# iostr911f register map
Registers are 16-bit, access not given, no defined reset value unless marked. A register's access mark holds for its fields unless they carry their own. Addresses are absolute; registers are grouped by the start of their names; [hi:lo] are bit positions; {n}, {i} and the like mark numbered series; 'fields as' and 'values as' point back to an identical list.

## SCU
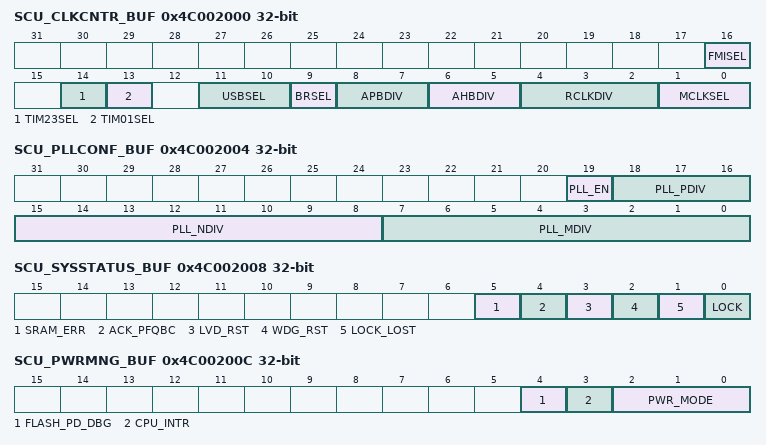
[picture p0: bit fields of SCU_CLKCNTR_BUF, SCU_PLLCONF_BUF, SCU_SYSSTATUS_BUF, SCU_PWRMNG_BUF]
0x4C002000 SCU_CLKCNTR_BUF 32-bit
  [16] FMISEL, [14] TIM23SEL, [13] TIM01SEL, [11:10] USBSEL, [9] BRSEL, [8:7] APBDIV, [6:5] AHBDIV, [4:2] RCLKDIV, [1:0] MCLKSEL
0x4C002004 SCU_PLLCONF_BUF 32-bit
  [19] PLL_EN, [18:16] PLL_PDIV, [15:8] PLL_NDIV, [7:0] PLL_MDIV
0x4C002008 SCU_SYSSTATUS_BUF 32-bit
  [5] SRAM_ERR, [4] ACK_PFQBC, [3] LVD_RST, [2] WDG_RST, [1] LOCK_LOST, [0] LOCK
0x4C00200C SCU_PWRMNG_BUF 32-bit
  [4] FLASH_PD_DBG, [3] CPU_INTR, [2:0] PWR_MODE
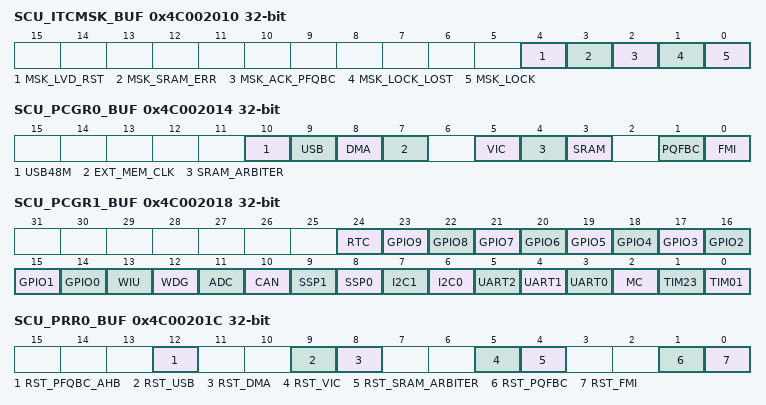
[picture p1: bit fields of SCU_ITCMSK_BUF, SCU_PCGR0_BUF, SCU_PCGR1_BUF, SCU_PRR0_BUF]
0x4C002010 SCU_ITCMSK_BUF 32-bit
  [4] MSK_LVD_RST, [3] MSK_SRAM_ERR, [2] MSK_ACK_PFQBC, [1] MSK_LOCK_LOST, [0] MSK_LOCK
0x4C002014 SCU_PCGR0_BUF 32-bit
  [10] USB48M, [9] USB, [8] DMA, [7] EXT_MEM_CLK, [5] VIC, [4] SRAM_ARBITER, [3] SRAM, [1] PQFBC, [0] FMI
0x4C002018 SCU_PCGR1_BUF 32-bit
  [24] RTC, [n+14] GPIO{n} (n=0..9), [13] WIU, [12] WDG, [11] ADC, [10] CAN, [9] SSP1, [8] SSP0, [7] I2C1, [6] I2C0, [5] UART2, [4] UART1, [3] UART0, [2] MC, [1] TIM23, [0] TIM01
0x4C00201C SCU_PRR0_BUF 32-bit
  [12] RST_PFQBC_AHB, [9] RST_USB, [8] RST_DMA, [5] RST_VIC, [4] RST_SRAM_ARBITER, [1] RST_PQFBC, [0] RST_FMI
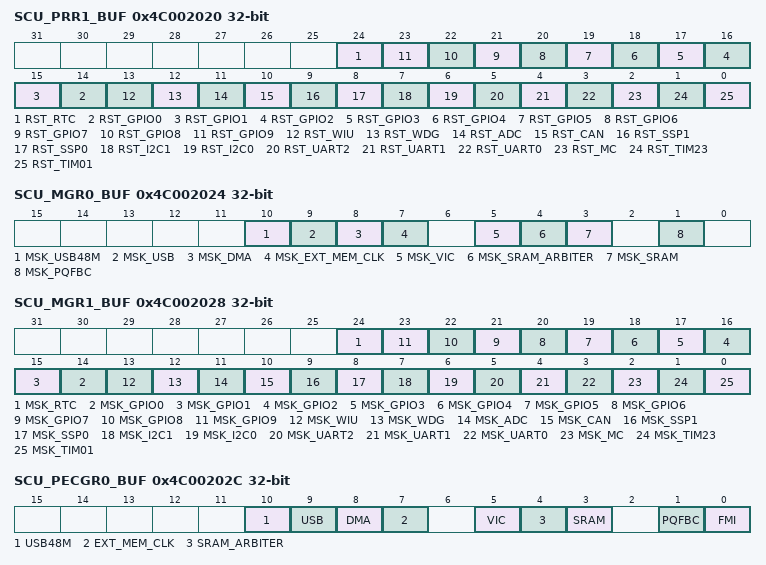
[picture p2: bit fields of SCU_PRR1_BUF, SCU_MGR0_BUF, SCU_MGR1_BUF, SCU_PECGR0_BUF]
0x4C002020 SCU_PRR1_BUF 32-bit
  [24] RST_RTC, [n+14] RST_GPIO{n} (n=0..9), [13] RST_WIU, [12] RST_WDG, [11] RST_ADC, [10] RST_CAN, [9] RST_SSP1, [8] RST_SSP0, [7] RST_I2C1, [6] RST_I2C0, [5] RST_UART2, [4] RST_UART1, [3] RST_UART0, [2] RST_MC, [1] RST_TIM23, [0] RST_TIM01
0x4C002024 SCU_MGR0_BUF 32-bit
  [10] MSK_USB48M, [9] MSK_USB, [8] MSK_DMA, [7] MSK_EXT_MEM_CLK, [5] MSK_VIC, [4] MSK_SRAM_ARBITER, [3] MSK_SRAM, [1] MSK_PQFBC
0x4C002028 SCU_MGR1_BUF 32-bit
  [24] MSK_RTC, [n+14] MSK_GPIO{n} (n=0..9), [13] MSK_WIU, [12] MSK_WDG, [11] MSK_ADC, [10] MSK_CAN, [9] MSK_SSP1, [8] MSK_SSP0, [7] MSK_I2C1, [6] MSK_I2C0, [5] MSK_UART2, [4] MSK_UART1, [3] MSK_UART0, [2] MSK_MC, [1] MSK_TIM23, [0] MSK_TIM01
0x4C00202C SCU_PECGR0_BUF 32-bit
  fields as SCU_PCGR0_BUF
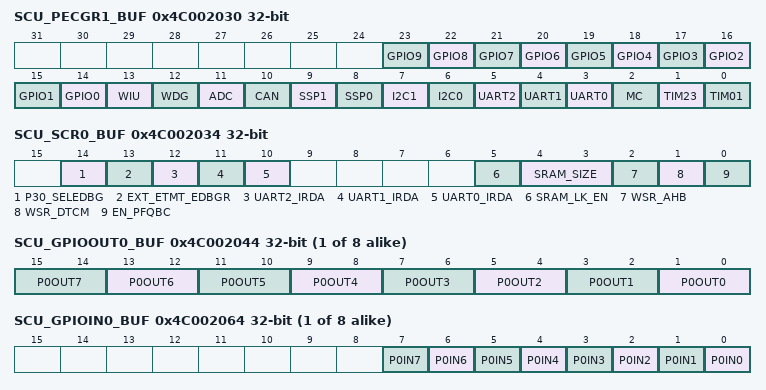
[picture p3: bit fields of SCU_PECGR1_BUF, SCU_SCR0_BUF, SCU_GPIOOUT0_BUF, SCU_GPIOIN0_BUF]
0x4C002030 SCU_PECGR1_BUF 32-bit
  [n+14] GPIO{n} (n=0..9), [13] WIU, [12] WDG, [11] ADC, [10] CAN, [9] SSP1, [8] SSP0, [7] I2C1, [6] I2C0, [5] UART2, [4] UART1, [3] UART0, [2] MC, [1] TIM23, [0] TIM01
0x4C002034 SCU_SCR0_BUF 32-bit
  [14] P30_SELEDBG, [13] EXT_ETMT_EDBGR, [12] UART2_IRDA, [11] UART1_IRDA, [10] UART0_IRDA, [5] SRAM_LK_EN, [4:3] SRAM_SIZE, [2] WSR_AHB, [1] WSR_DTCM, [0] EN_PFQBC
0x4C002038 SCU_SCR1_BUF
0x4C00203C SCU_SCR2_BUF
{0x4C002044+4i} SCU_GPIOOUT{i}_BUF 32-bit (i=0..7)
  [2n+1:2n] P{i}OUT{n} (n=0..7)
{0x4C002064+4i} SCU_GPIOIN{i}_BUF 32-bit (i=0..7)
  [n] P{i}IN{n} (n=0..7)
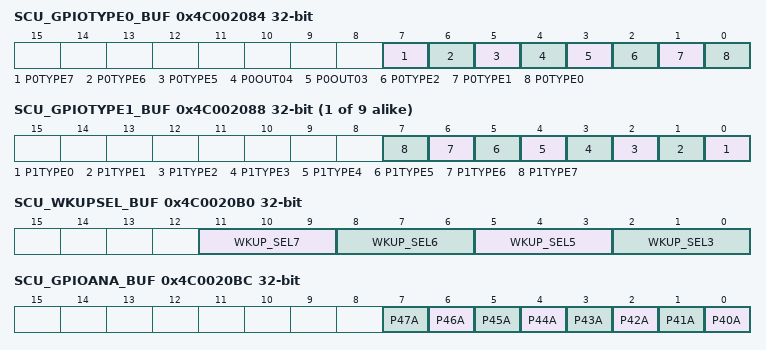
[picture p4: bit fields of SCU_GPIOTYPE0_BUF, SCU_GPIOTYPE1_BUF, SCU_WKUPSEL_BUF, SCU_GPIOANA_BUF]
0x4C002084 SCU_GPIOTYPE0_BUF 32-bit
  [7] P0TYPE7, [6] P0TYPE6, [5] P0TYPE5, [4] P0OUT04, [3] P0OUT03, [2] P0TYPE2, [1] P0TYPE1, [0] P0TYPE0
{0x4C002084+4i} SCU_GPIOTYPE{i}_BUF 32-bit (i=1..9)
  [n] P{i}TYPE{n} (n=0..7)
0x4C0020B0 SCU_WKUPSEL_BUF 32-bit
  [11:9] WKUP_SEL7, [8:6] WKUP_SEL6, [5:3] WKUP_SEL5, [2:0] WKUP_SEL3
0x4C0020BC SCU_GPIOANA_BUF 32-bit
  [n-40] P{n}A (n=40..47)
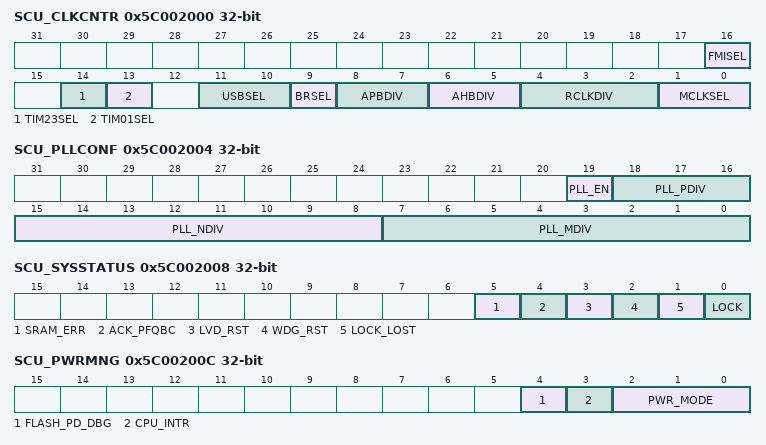
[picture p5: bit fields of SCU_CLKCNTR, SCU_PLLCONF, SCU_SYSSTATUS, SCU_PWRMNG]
0x5C002000 SCU_CLKCNTR 32-bit
  fields as SCU_CLKCNTR_BUF
0x5C002004 SCU_PLLCONF 32-bit
  [19] PLL_EN, [18:16] PLL_PDIV, [15:8] PLL_NDIV, [7:0] PLL_MDIV
0x5C002008 SCU_SYSSTATUS 32-bit
  fields as SCU_SYSSTATUS_BUF
0x5C00200C SCU_PWRMNG 32-bit
  [4] FLASH_PD_DBG, [3] CPU_INTR, [2:0] PWR_MODE
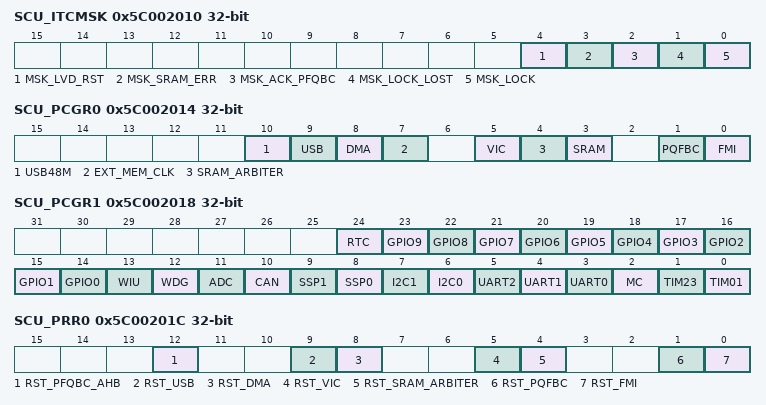
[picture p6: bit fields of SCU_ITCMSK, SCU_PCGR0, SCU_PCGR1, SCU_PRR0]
0x5C002010 SCU_ITCMSK 32-bit
  fields as SCU_ITCMSK_BUF
0x5C002014 SCU_PCGR0 32-bit
  fields as SCU_PCGR0_BUF
0x5C002018 SCU_PCGR1 32-bit
  fields as SCU_PCGR1_BUF
0x5C00201C SCU_PRR0 32-bit
  fields as SCU_PRR0_BUF
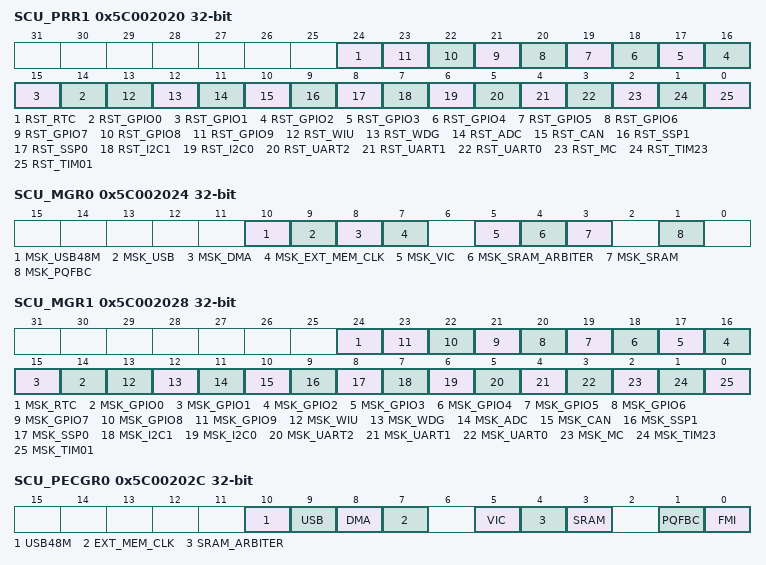
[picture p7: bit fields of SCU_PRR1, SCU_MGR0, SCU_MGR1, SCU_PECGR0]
0x5C002020 SCU_PRR1 32-bit
  fields as SCU_PRR1_BUF
0x5C002024 SCU_MGR0 32-bit
  fields as SCU_MGR0_BUF
0x5C002028 SCU_MGR1 32-bit
  fields as SCU_MGR1_BUF
0x5C00202C SCU_PECGR0 32-bit
  fields as SCU_PCGR0_BUF
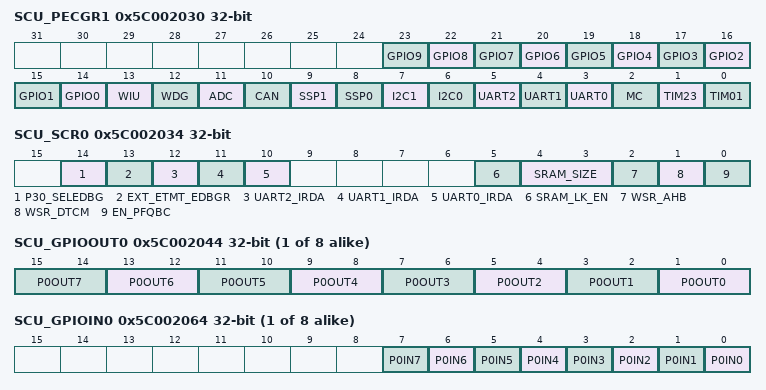
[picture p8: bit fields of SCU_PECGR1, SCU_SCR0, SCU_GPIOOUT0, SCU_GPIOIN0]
0x5C002030 SCU_PECGR1 32-bit
  fields as SCU_PECGR1_BUF
0x5C002034 SCU_SCR0 32-bit
  fields as SCU_SCR0_BUF
0x5C002038 SCU_SCR1
0x5C00203C SCU_SCR2
{0x5C002044+4i} SCU_GPIOOUT{i} 32-bit (i=0..7)
  [2n+1:2n] P{i}OUT{n} (n=0..7)
{0x5C002064+4i} SCU_GPIOIN{i} 32-bit (i=0..7)
  [n] P{i}IN{n} (n=0..7)
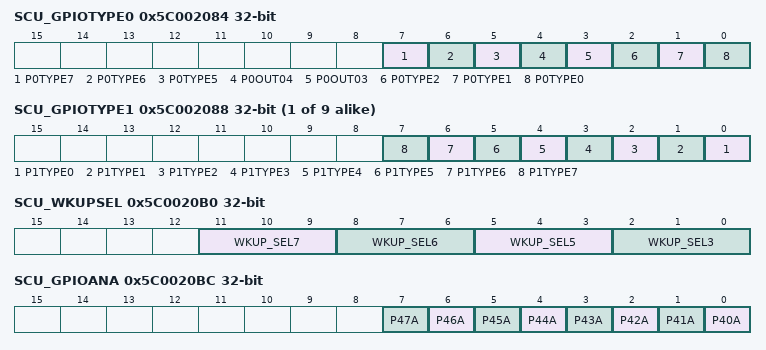
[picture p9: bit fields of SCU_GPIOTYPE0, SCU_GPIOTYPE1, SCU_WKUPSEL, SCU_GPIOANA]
0x5C002084 SCU_GPIOTYPE0 32-bit
  fields as SCU_GPIOTYPE0_BUF
{0x5C002084+4i} SCU_GPIOTYPE{i} 32-bit (i=1..9)
  [n] P{i}TYPE{n} (n=0..7)
0x5C0020B0 SCU_WKUPSEL 32-bit
  [11:9] WKUP_SEL7, [8:6] WKUP_SEL6, [5:3] WKUP_SEL5, [2:0] WKUP_SEL3
0x5C0020BC SCU_GPIOANA 32-bit
  [n-40] P{n}A (n=40..47)
